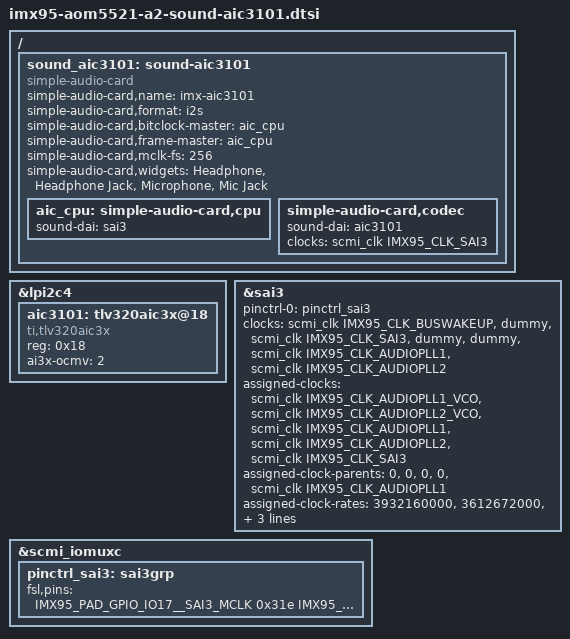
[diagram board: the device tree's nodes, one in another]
/ {
	sound_aic3101: sound-aic3101 {
		compatible = "simple-audio-card";
		simple-audio-card,name = "imx-aic3101";
		simple-audio-card,format = "i2s";
		simple-audio-card,bitclock-master = <&aic_cpu>;
		simple-audio-card,frame-master = <&aic_cpu>;
		simple-audio-card,mclk-fs = <256>;

		simple-audio-card,widgets =
			"Headphone", "Headphone Jack",
			"Microphone", "Mic Jack";

		aic_cpu: simple-audio-card,cpu {
			sound-dai = <&sai3>;
		};
		simple-audio-card,codec {
			sound-dai = <&aic3101>;
			clocks = <&scmi_clk IMX95_CLK_SAI3>;
		};
	};
};

&lpi2c4 {
	aic3101: tlv320aic3x@18 {
		#sound-dai-cells = <0>;
		compatible = "ti,tlv320aic3x";
		reg = <0x18>;
                ai3x-ocmv = <2>;   /* HP common-mode 1.65V — datasheet Table 5 for 3.3V AVDD/DRVDD, 1.8V DVDD */
        };
};

&sai3 {
	#sound-dai-cells = <0>;
	pinctrl-names = "default";
	pinctrl-0 = <&pinctrl_sai3>;

	clocks = <&scmi_clk IMX95_CLK_BUSWAKEUP>, <&dummy>,
		 <&scmi_clk IMX95_CLK_SAI3>, <&dummy>,
		 <&dummy>, <&scmi_clk IMX95_CLK_AUDIOPLL1>,
		 <&scmi_clk IMX95_CLK_AUDIOPLL2>;
	clock-names = "bus", "mclk0", "mclk1", "mclk2", "mclk3", "pll8k", "pll11k";

	assigned-clocks = <&scmi_clk IMX95_CLK_AUDIOPLL1_VCO>,
			  <&scmi_clk IMX95_CLK_AUDIOPLL2_VCO>,
			  <&scmi_clk IMX95_CLK_AUDIOPLL1>,
			  <&scmi_clk IMX95_CLK_AUDIOPLL2>,
			  <&scmi_clk IMX95_CLK_SAI3>;
	assigned-clock-parents = <0>, <0>, <0>, <0>,
				 <&scmi_clk IMX95_CLK_AUDIOPLL1>;
	assigned-clock-rates = <3932160000>, <3612672000>,
			       <393216000>, <361267200>, <12288000>;
	fsl,sai-mclk-direction-output;
	fsl,sai-synchronous-rx;
};

&scmi_iomuxc {
	pinctrl_sai3: sai3grp {
		fsl,pins = <
			IMX95_PAD_GPIO_IO17__SAI3_MCLK			0x31e
			IMX95_PAD_GPIO_IO18__SAI3_RX_BCLK		0x31e
			IMX95_PAD_GPIO_IO19__SAI3_RX_SYNC		0x31e
			IMX95_PAD_GPIO_IO20__SAI3_RX_DATA_BIT0		0x31e
			IMX95_PAD_GPIO_IO21__SAI3_TX_DATA_BIT0		0x31e
		>;
	};
};
